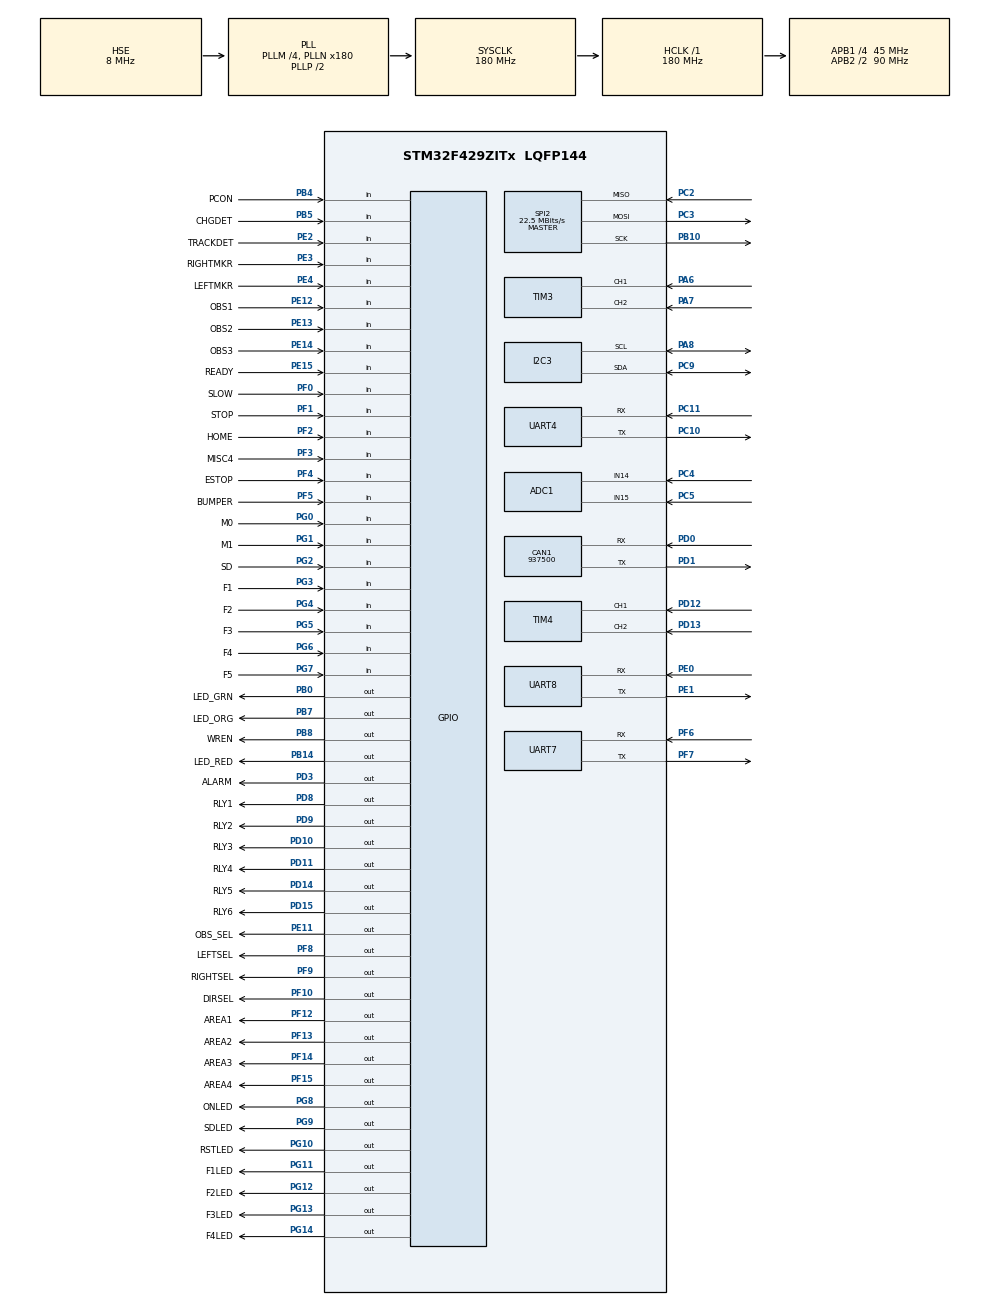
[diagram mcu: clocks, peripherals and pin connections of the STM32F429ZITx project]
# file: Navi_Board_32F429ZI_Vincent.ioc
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ADC1.Channel-0\#ChannelRegularConversion=ADC_CHANNEL_15
ADC1.NbrOfConversionFlag=1
ADC1.Rank-0\#ChannelRegularConversion=1
ADC1.SamplingTime-0\#ChannelRegularConversion=ADC_SAMPLETIME_3CYCLES
ADC1.master=1
CAN1.CalculateBaudRate=937500
CAN1.CalculateTimeBit=1066
CAN1.CalculateTimeQuantum=355.55555555555554
Dma.Request0=UART4_RX
Dma.Request1=UART7_RX
Dma.Request2=UART8_RX
Dma.UART4_RX.0.Direction=DMA_PERIPH_TO_MEMORY
Dma.UART4_RX.0.FIFOMode=DMA_FIFOMODE_DISABLE
Dma.UART4_RX.0.Instance=DMA1_Stream2
Dma.UART4_RX.0.MemDataAlignment=DMA_MDATAALIGN_BYTE
Dma.UART4_RX.0.MemInc=DMA_MINC_ENABLE
Dma.UART4_RX.0.Mode=DMA_NORMAL
Dma.UART4_RX.0.PeriphDataAlignment=DMA_PDATAALIGN_BYTE
Dma.UART4_RX.0.PeriphInc=DMA_PINC_DISABLE
Dma.UART4_RX.0.Priority=DMA_PRIORITY_LOW
Dma.UART7_RX.1.Direction=DMA_PERIPH_TO_MEMORY
Dma.UART7_RX.1.FIFOMode=DMA_FIFOMODE_DISABLE
Dma.UART7_RX.1.Instance=DMA1_Stream3
Dma.UART7_RX.1.MemDataAlignment=DMA_MDATAALIGN_BYTE
Dma.UART7_RX.1.MemInc=DMA_MINC_ENABLE
Dma.UART7_RX.1.Mode=DMA_NORMAL
Dma.UART7_RX.1.PeriphDataAlignment=DMA_PDATAALIGN_BYTE
Dma.UART7_RX.1.PeriphInc=DMA_PINC_DISABLE
Dma.UART7_RX.1.Priority=DMA_PRIORITY_LOW
Dma.UART8_RX.2.Direction=DMA_PERIPH_TO_MEMORY
Dma.UART8_RX.2.FIFOMode=DMA_FIFOMODE_DISABLE
Dma.UART8_RX.2.Instance=DMA1_Stream6
Dma.UART8_RX.2.MemDataAlignment=DMA_MDATAALIGN_BYTE
Dma.UART8_RX.2.MemInc=DMA_MINC_ENABLE
Dma.UART8_RX.2.Mode=DMA_NORMAL
Dma.UART8_RX.2.PeriphDataAlignment=DMA_PDATAALIGN_BYTE
Dma.UART8_RX.2.PeriphInc=DMA_PINC_DISABLE
Dma.UART8_RX.2.Priority=DMA_PRIORITY_LOW
FREERTOS.INCLUDE_vTaskDelayUntil=1
FREERTOS.Tasks01=PCTask,2,128,StartPcTask,Default,NULL,Dynamic,NULL,NULL;MotorTask,-2,128,StartMotorTask,Default,NULL,Dynamic,NULL,NULL;ActionTask,-1,128,StartActionTask,Default,NULL,Dynamic,NULL,NULL;IOTask,0,128,StartIOControlTask,Default,NULL,Dynamic,NULL,NULL
FREERTOS.configUSE_NEWLIB_REENTRANT=1
IWDG.Prescaler=IWDG_PRESCALER_16
IWDG.Reload=3999
Mcu.Family=STM32F4
Mcu.Name=STM32F429ZITx
Mcu.Package=LQFP144
NVIC.DMA1_Stream2_IRQn=true\:5\:0\:true\:false\:true\:true\:false\:true\:true
NVIC.DMA1_Stream3_IRQn=true\:5\:0\:true\:false\:true\:true\:false\:true\:true
NVIC.DMA1_Stream6_IRQn=true\:5\:0\:false\:false\:true\:true\:false\:true\:true
NVIC.PriorityGroup=NVIC_PRIORITYGROUP_4
NVIC.TIM3_IRQn=true\:5\:0\:false\:false\:true\:true\:true\:true\:true
NVIC.TIM4_IRQn=true\:5\:0\:false\:false\:true\:true\:true\:true\:true
NVIC.TIM6_DAC_IRQn=true\:15\:0\:false\:false\:true\:false\:false\:true\:true
NVIC.TimeBase=TIM6_DAC_IRQn
NVIC.TimeBaseIP=TIM6
NVIC.UART4_IRQn=true\:5\:0\:true\:false\:true\:true\:true\:true\:true
NVIC.UART7_IRQn=true\:5\:0\:true\:false\:true\:true\:true\:true\:true
NVIC.UART8_IRQn=true\:5\:0\:false\:false\:true\:true\:true\:true\:true
PA0/WKUP.Signal=S_TIM5_CH1
PA1.Signal=S_TIM5_CH2
PA10.Signal=USART1_RX
PA12.Signal=USART1_RTS
PA13.Mode=Trace_Asynchronous_SW
PA13.Signal=SYS_JTMS-SWDIO
PA14.Mode=Trace_Asynchronous_SW
PA14.Signal=SYS_JTCK-SWCLK
PA2.Signal=USART2_TX
PA3.Signal=USART2_RX
PA6.Signal=S_TIM3_CH1
PA7.Signal=S_TIM3_CH2
PA8.Mode=I2C
PA8.Signal=I2C3_SCL
PA9.Signal=USART1_TX
PB0.GPIO_Label=LED_GRN
PB0.Signal=GPIO_Output
PB10.Mode=Full_Duplex_Master
PB10.Signal=SPI2_SCK
PB12.Signal=SPI2_NSS
PB14.GPIO_Label=LED_RED
PB14.Signal=GPIO_Output
PB3.Mode=Trace_Asynchronous_SW
PB3.Signal=SYS_JTDO-SWO
PB4.GPIO_Label=PCON
PB4.Signal=GPIO_Input
PB5.GPIO_Label=CHGDET
PB5.Signal=GPIO_Input
PB6.Signal=I2C1_SCL
PB7.GPIO_Label=LED_ORG
PB7.Signal=GPIO_Output
PB8.GPIO_Label=WREN
PB8.Signal=GPIO_Output
PC10.Mode=Asynchronous
PC10.Signal=UART4_TX
PC11.Mode=Asynchronous
PC11.Signal=UART4_RX
PC12.Signal=UART5_TX
PC2.Mode=Full_Duplex_Master
PC2.Signal=SPI2_MISO
PC3.Mode=Full_Duplex_Master
PC3.Signal=SPI2_MOSI
PC4.Signal=ADCx_IN14
PC5.Signal=ADCx_IN15
PC9.Mode=I2C
PC9.Signal=I2C3_SDA
PD0.Mode=CAN_Activate
PD0.Signal=CAN1_RX
PD1.Mode=CAN_Activate
PD1.Signal=CAN1_TX
PD10.GPIO_Label=RLY3
PD10.Signal=GPIO_Output
PD11.GPIO_Label=RLY4
PD11.Signal=GPIO_Output
PD12.Signal=S_TIM4_CH1
PD13.Signal=S_TIM4_CH2
PD14.GPIO_Label=RLY5
PD14.Signal=GPIO_Output
PD15.GPIO_Label=RLY6
PD15.Signal=GPIO_Output
PD2.Signal=UART5_RX
PD3.GPIO_Label=ALARM
PD3.Signal=GPIO_Output
PD8.GPIO_Label=RLY1
PD8.Signal=GPIO_Output
PD9.GPIO_Label=RLY2
PD9.Signal=GPIO_Output
PE0.Mode=Asynchronous
PE0.Signal=UART8_RX
PE1.Mode=Asynchronous
PE1.Signal=UART8_TX
PE11.GPIO_Label=OBS_SEL
PE11.Signal=GPIO_Output
PE12.GPIO_Label=OBS1
PE12.Signal=GPIO_Input
PE13.GPIO_Label=OBS2
PE13.Signal=GPIO_Input
PE14.GPIO_Label=OBS3
PE14.Signal=GPIO_Input
PE15.GPIO_Label=READY
PE15.Signal=GPIO_Input
PE2.GPIO_Label=TRACKDET
PE2.Signal=GPIO_Input
PE3.GPIO_Label=RIGHTMKR
PE3.Signal=GPIO_Input
PE4.GPIO_Label=LEFTMKR
PE4.Signal=GPIO_Input
PE5.Signal=S_TIM9_CH1
PE6.Signal=S_TIM9_CH2
PE9.Signal=S_TIM1_CH1
PF0.GPIO_Label=SLOW
PF0.Signal=GPIO_Input
PF1.GPIO_Label=STOP
PF1.Signal=GPIO_Input
PF10.GPIO_Label=DIRSEL
PF10.Signal=GPIO_Output
PF12.GPIO_Label=AREA1
PF12.Signal=GPIO_Output
PF13.GPIO_Label=AREA2
PF13.Signal=GPIO_Output
PF14.GPIO_Label=AREA3
PF14.Signal=GPIO_Output
PF15.GPIO_Label=AREA4
PF15.Signal=GPIO_Output
PF2.GPIO_Label=HOME
PF2.Signal=GPIO_Input
PF3.GPIO_Label=MISC4
PF3.Signal=GPIO_Input
PF4.GPIO_Label=ESTOP
PF4.Signal=GPIO_Input
PF5.GPIO_Label=BUMPER
PF5.Signal=GPIO_Input
PF6.Mode=Asynchronous
PF6.Signal=UART7_RX
PF7.Mode=Asynchronous
PF7.Signal=UART7_TX
PF8.GPIO_Label=LEFTSEL
PF8.Signal=GPIO_Output
PF9.GPIO_Label=RIGHTSEL
PF9.Signal=GPIO_Output
PG0.GPIO_Label=M0
PG0.Signal=GPIO_Input
PG1.GPIO_Label=M1
PG1.Signal=GPIO_Input
PG10.GPIO_Label=RSTLED
PG10.Signal=GPIO_Output
PG11.GPIO_Label=F1LED
PG11.Signal=GPIO_Output
PG12.GPIO_Label=F2LED
PG12.Signal=GPIO_Output
PG13.GPIO_Label=F3LED
PG13.Signal=GPIO_Output
PG14.GPIO_Label=F4LED
PG14.Signal=GPIO_Output
PG2.GPIO_Label=SD
PG2.Signal=GPIO_Input
PG3.GPIO_Label=F1
PG3.Signal=GPIO_Input
PG4.GPIO_Label=F2
PG4.Signal=GPIO_Input
PG5.GPIO_Label=F3
PG5.Signal=GPIO_Input
PG6.GPIO_Label=F4
PG6.Signal=GPIO_Input
PG7.GPIO_Label=F5
PG7.Signal=GPIO_Input
PG8.GPIO_Label=ONLED
PG8.Signal=GPIO_Output
PG9.GPIO_Label=SDLED
PG9.Signal=GPIO_Output
PH0/OSC_IN.Mode=HSE-External-Oscillator
PH0/OSC_IN.Signal=RCC_OSC_IN
PH1/OSC_OUT.Mode=HSE-External-Oscillator
PH1/OSC_OUT.Signal=RCC_OSC_OUT
ProjectManager.HeapSize=0x200
ProjectManager.StackSize=0x400
ProjectManager.TargetToolchain=STM32CubeIDE
RCC.48MHZClocksFreq_Value=90000000
RCC.AHBFreq_Value=180000000
RCC.APB1CLKDivider=RCC_HCLK_DIV4
RCC.APB1Freq_Value=45000000
RCC.APB1TimFreq_Value=90000000
RCC.APB2CLKDivider=RCC_HCLK_DIV2
RCC.APB2Freq_Value=90000000
RCC.APB2TimFreq_Value=180000000
RCC.CortexFreq_Value=180000000
RCC.HCLKFreq_Value=180000000
RCC.HSE_VALUE=8000000
RCC.HSI_VALUE=16000000
RCC.LSE_VALUE=32768
RCC.PLLM=4
RCC.PLLN=180
RCC.PLLSourceVirtual=RCC_PLLSOURCE_HSE
RCC.SYSCLKFreq_VALUE=180000000
RCC.SYSCLKSource=RCC_SYSCLKSOURCE_PLLCLK
RCC.VCOOutputFreq_Value=360000000
SH.ADCx_IN14.0=ADC1_IN14,IN14
SH.ADCx_IN15.0=ADC1_IN15,IN15
SH.S_TIM1_CH1.0=TIM1_CH1
SH.S_TIM3_CH1.0=TIM3_CH1,Encoder_Interface
SH.S_TIM3_CH2.0=TIM3_CH2,Encoder_Interface
SH.S_TIM4_CH1.0=TIM4_CH1,Encoder_Interface
SH.S_TIM4_CH2.0=TIM4_CH2,Encoder_Interface
SH.S_TIM5_CH1.0=TIM5_CH1
SH.S_TIM5_CH2.0=TIM5_CH2
SH.S_TIM9_CH1.0=TIM9_CH1
SH.S_TIM9_CH2.0=TIM9_CH2
SPI2.CalculateBaudRate=22.5 MBits/s
SPI2.Direction=SPI_DIRECTION_2LINES
SPI2.Mode=SPI_MODE_MASTER
SPI2.VirtualType=VM_MASTER
TIM3.EncoderMode=TIM_ENCODERMODE_TI12
TIM4.EncoderMode=TIM_ENCODERMODE_TI12
UART4.VirtualMode=Asynchronous
UART7.VirtualMode=Asynchronous
UART8.VirtualMode=Asynchronous
VP_FREERTOS_VS_CMSIS_V1.Mode=CMSIS_V1
VP_IWDG_VS_IWDG.Mode=IWDG_Activate
VP_SYS_VS_tim6.Mode=TIM6
board=custom

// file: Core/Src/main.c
/* USER CODE BEGIN Header */
/**
  ******************************************************************************
  * @file           : main.c
  * @brief          : Main program body
  ******************************************************************************
  * @attention
  *
  * Copyright (c) 2022 STMicroelectronics.
  * All rights reserved.
  *
  * This software is licensed under terms that can be found in the LICENSE file
  * in the root directory of this software component.
  * If no LICENSE file comes with this software, it is provided AS-IS.
  *
  ******************************************************************************
  */
/* USER CODE END Header */
#include "main.h"
#include "cmsis_os.h"

/* USER CODE BEGIN Includes */
#include "roboteq_HAL.h"
#include "stdio.h"
/* USER CODE END Includes */

/* USER CODE BEGIN PTD */
/** \brief Structure layout that contains the version number of a software
 *         program.
 */
typedef struct
{
  uint8_t major;  /**< Major part of the version number. */
  uint8_t minor;  /**< Minor part of the version number. */
  uint8_t patch;  /**< Patch part of the version number. */
} tVersionInfo;
/** \brief Function-like macro for reading out the bootloader's version
 *         number.
 */
#define FIRM_VERSION_GET()  ((tVersionInfo const * const)0x080001ac)

/** \brief Constant variable that contains the bootloader version number.
 *         The ".version" section attribute was added, allowing the linker
 *         to find it and place it at a fixed address in the memory map.
 *         Note that approach is GCC compiler/linker specific and will
 *         need adjusting in case another toolchain is used.
 */
const tVersionInfo FirmwareVersion __attribute__ ((section (".version"))) =
{
  .major = FIRM_VERSION_CORE_MAIN,
  .minor = FIRM_VERSION_CORE_MINOR,
  .patch = FIRM_VERSION_CORE_PATCH
};
/* USER CODE END PTD */

/* USER CODE BEGIN PM */
#define ITM_Port32(n)   (*((volatile unsigned long *)(0xE0000000+4*n)))
/* USER CODE END PM */

 ADC_HandleTypeDef hadc1;

CAN_HandleTypeDef hcan1;

I2C_HandleTypeDef hi2c3;

IWDG_HandleTypeDef hiwdg;

SPI_HandleTypeDef hspi2;

TIM_HandleTypeDef htim3;
TIM_HandleTypeDef htim4;

UART_HandleTypeDef huart4;
UART_HandleTypeDef huart7;
UART_HandleTypeDef huart8;
DMA_HandleTypeDef hdma_uart4_rx;
DMA_HandleTypeDef hdma_uart7_rx;
DMA_HandleTypeDef hdma_uart8_rx;

osThreadId PCTaskHandle;
osThreadId MotorTaskHandle;
osThreadId ActionTaskHandle;
osThreadId IOTaskHandle;
/* USER CODE BEGIN PV */
uint8_t FirmVersionMajor;
uint8_t FirmVersionMinor;
uint8_t FirmVersionPatch;

uint32_t counter_l = 0;
uint32_t counter_r = 0;
int16_t count_l = 0;
int16_t count_r = 0;
int16_t speed_l;
int16_t speed_r;
int32_t oldpos_l = 0;
int32_t oldpos_r = 0;
uint8_t indx = 0;

int32_t min_enc_value = -32768;
int32_t max_enc_value = 32767;
int32_t prev_lencoder = 0;
int32_t prev_rencoder = 0;
int32_t enc;

int32_t lmult = 0;
int32_t rmult = 0;

int32_t left = 1;
int32_t right = 1;

int32_t encoder_min = -32768;  //-2,147,483,648; //-65536;
int32_t encoder_max = 32767;  // 2,147,483,647; //65536;
int32_t encoder_low_wrap;
int32_t encoder_high_wrap;

extern FLAG fUART_roboteq;
extern FLAG fUART_deck;
extern FLAG fUART_lifter;
extern FLAG fUART_pc;
extern struct {
	float2int wheel_circumference;
	float2int track_width;
	float2int upper_linear_v;
	float2int slow_linear_v;
	uint8_t gear_ratio;
	int32int8 cpr;
	uint8_t deck_gear_ratio;
	int32int8 deck_cpr;
}motorpara;
extern int32_t TIMEOUT;
extern uint32_t motion_exec_state;
/* USER CODE END PV */

void SystemClock_Config(void);
static void MX_GPIO_Init(void);
static void MX_ADC1_Init(void);
static void MX_DMA_Init(void);
static void MX_CAN1_Init(void);
static void MX_I2C3_Init(void);
static void MX_IWDG_Init(void);
static void MX_SPI2_Init(void);
static void MX_TIM3_Init(void);
static void MX_TIM4_Init(void);
static void MX_UART4_Init(void);
static void MX_UART7_Init(void);
static void MX_UART8_Init(void);
void StartPcTask(void const * argument);
void StartMotorTask(void const * argument);
void StartActionTask(void const * argument);
void StartIOControlTask(void const * argument);

/* USER CODE BEGIN PFP */
extern uint8_t Roboteq_Init (void);
extern void Sending_Data2Pc_callback(int interval_rate);
extern uint8_t Pc_Init();
extern uint8_t Deck_Init();
extern void IO_Control();
extern void Exec_Action();
extern void Send_Querydata2PC();
extern void Receive_PC_Command();
extern void Led_Green();
/* USER CODE END PFP */
void TIM1_IC_INT(TIM_HandleTypeDef* htim);
int MagTapePos(void);

/* USER CODE BEGIN 0 */
int _write(int file, char *ptr, int len)
{
  /* Implement your write code here, this is used by puts and printf for example */
  int i=0;
  for(i=0 ; i<len ; i++)
    ITM_SendChar((*ptr++));
  return len;
}
/* USER CODE END 0 */

int main(void)
{

  /* MCU Configuration--------------------------------------------------------*/

  /* Reset of all peripherals, Initializes the Flash interface and the Systick. */
  HAL_Init();

  /* Configure the system clock */
  SystemClock_Config();

  /* USER CODE BEGIN SysInit */
  ITM_Port32(31) = 1;
  /* USER CODE END SysInit */

  /* Initialize all configured peripherals */
  MX_GPIO_Init();
  MX_ADC1_Init();
  MX_DMA_Init();
  MX_CAN1_Init();
  MX_I2C3_Init();
  //MX_IWDG_Init();
  MX_SPI2_Init();
  MX_TIM3_Init();
  MX_TIM4_Init();
  MX_UART4_Init();
  MX_UART7_Init();
  MX_UART8_Init();
  /* USER CODE BEGIN 2 */
  ITM_Port32(31) = 2;
  /* USER CODE END 2 */

  /* Create the thread(s) */
  /* definition and creation of PCTask */
  osThreadDef(PCTask, StartPcTask, osPriorityHigh, 0, 128); //Receive PC command here: priority: HIGH
  PCTaskHandle = osThreadCreate(osThread(PCTask), NULL);

  /* definition and creation of MotorTask */
  osThreadDef(MotorTask, StartMotorTask, osPriorityLow, 0, 128); //Sending Query to the PC
  MotorTaskHandle = osThreadCreate(osThread(MotorTask), NULL);

  /* definition and creation of ActionTask */
  osThreadDef(ActionTask, StartActionTask, osPriorityBelowNormal, 0, 128); //Action Execuation
  ActionTaskHandle = osThreadCreate(osThread(ActionTask), NULL);

  /* definition and creation of IOTask */
  osThreadDef(IOTask, StartIOControlTask, osPriorityNormal, 0, 128); //Initize IOs for the operation
  IOTaskHandle = osThreadCreate(osThread(IOTask), NULL);

  /* Start scheduler */
  osKernelStart(); //Kicks off the main program threads (4x)

  /* We should never get here as control is now taken by the scheduler */
  /* Infinite loop */
  while (1)
  {

  }
}

void SystemClock_Config(void)
{
  RCC_OscInitTypeDef RCC_OscInitStruct = {0};
  RCC_ClkInitTypeDef RCC_ClkInitStruct = {0};

  /** Configure the main internal regulator output voltage
  */
  __HAL_RCC_PWR_CLK_ENABLE();
  __HAL_PWR_VOLTAGESCALING_CONFIG(PWR_REGULATOR_VOLTAGE_SCALE1);

  /** Initializes the RCC Oscillators according to the specified parameters
  * in the RCC_OscInitTypeDef structure.
  */
  RCC_OscInitStruct.OscillatorType = RCC_OSCILLATORTYPE_LSI|RCC_OSCILLATORTYPE_HSE;
  RCC_OscInitStruct.HSEState = RCC_HSE_ON;
  RCC_OscInitStruct.LSIState = RCC_LSI_ON;
  RCC_OscInitStruct.PLL.PLLState = RCC_PLL_ON;
  RCC_OscInitStruct.PLL.PLLSource = RCC_PLLSOURCE_HSE;
  RCC_OscInitStruct.PLL.PLLM = 4;
  RCC_OscInitStruct.PLL.PLLN = 180;
  RCC_OscInitStruct.PLL.PLLP = RCC_PLLP_DIV2;
  RCC_OscInitStruct.PLL.PLLQ = 4;
  if (HAL_RCC_OscConfig(&RCC_OscInitStruct) != HAL_OK)
  {
    Error_Handler();
  }

  /** Activate the Over-Drive mode
  */
  if (HAL_PWREx_EnableOverDrive() != HAL_OK)
  {
    Error_Handler();
  }

  /** Initializes the CPU, AHB and APB buses clocks
  */
  RCC_ClkInitStruct.ClockType = RCC_CLOCKTYPE_HCLK|RCC_CLOCKTYPE_SYSCLK
                              |RCC_CLOCKTYPE_PCLK1|RCC_CLOCKTYPE_PCLK2;
  RCC_ClkInitStruct.SYSCLKSource = RCC_SYSCLKSOURCE_PLLCLK;
  RCC_ClkInitStruct.AHBCLKDivider = RCC_SYSCLK_DIV1;
  RCC_ClkInitStruct.APB1CLKDivider = RCC_HCLK_DIV4;
  RCC_ClkInitStruct.APB2CLKDivider = RCC_HCLK_DIV2;

  if (HAL_RCC_ClockConfig(&RCC_ClkInitStruct, FLASH_LATENCY_5) != HAL_OK)
  {
    Error_Handler();
  }
}

static void MX_ADC1_Init(void)
{

  ADC_ChannelConfTypeDef sConfig = {0};

  /** Configure the global features of the ADC (Clock, Resolution, Data Alignment and number of conversion)
  */
  hadc1.Instance = ADC1;
  hadc1.Init.ClockPrescaler = ADC_CLOCK_SYNC_PCLK_DIV4;
  hadc1.Init.Resolution = ADC_RESOLUTION_12B;
  hadc1.Init.ScanConvMode = DISABLE;
  hadc1.Init.ContinuousConvMode = DISABLE;
  hadc1.Init.DiscontinuousConvMode = DISABLE;
  hadc1.Init.ExternalTrigConvEdge = ADC_EXTERNALTRIGCONVEDGE_NONE;
  hadc1.Init.ExternalTrigConv = ADC_SOFTWARE_START;
  hadc1.Init.DataAlign = ADC_DATAALIGN_RIGHT;
  hadc1.Init.NbrOfConversion = 1;
  hadc1.Init.DMAContinuousRequests = DISABLE;
  hadc1.Init.EOCSelection = ADC_EOC_SINGLE_CONV;
  if (HAL_ADC_Init(&hadc1) != HAL_OK)
  {
    Error_Handler();
  }

  /** Configure for the selected ADC regular channel its corresponding rank in the sequencer and its sample time.
  */
  sConfig.Channel = ADC_CHANNEL_15;
  sConfig.Rank = 1;
  sConfig.SamplingTime = ADC_SAMPLETIME_3CYCLES;
  if (HAL_ADC_ConfigChannel(&hadc1, &sConfig) != HAL_OK)
  {
    Error_Handler();
  }

}

static void MX_CAN1_Init(void)
{

  hcan1.Instance = CAN1;
  hcan1.Init.Prescaler = 16;
  hcan1.Init.Mode = CAN_MODE_NORMAL;
  hcan1.Init.SyncJumpWidth = CAN_SJW_1TQ;
  hcan1.Init.TimeSeg1 = CAN_BS1_1TQ;
  hcan1.Init.TimeSeg2 = CAN_BS2_1TQ;
  hcan1.Init.TimeTriggeredMode = DISABLE;
  hcan1.Init.AutoBusOff = DISABLE;
  hcan1.Init.AutoWakeUp = DISABLE;
  hcan1.Init.AutoRetransmission = DISABLE;
  hcan1.Init.ReceiveFifoLocked = DISABLE;
  hcan1.Init.TransmitFifoPriority = DISABLE;
  if (HAL_CAN_Init(&hcan1) != HAL_OK)
  {
    Error_Handler();
  }

}

static void MX_I2C3_Init(void)
{

  hi2c3.Instance = I2C3;
  hi2c3.Init.ClockSpeed = 100000;
  hi2c3.Init.DutyCycle = I2C_DUTYCYCLE_2;
  hi2c3.Init.OwnAddress1 = 0;
  hi2c3.Init.AddressingMode = I2C_ADDRESSINGMODE_7BIT;
  hi2c3.Init.DualAddressMode = I2C_DUALADDRESS_DISABLE;
  hi2c3.Init.OwnAddress2 = 0;
  hi2c3.Init.GeneralCallMode = I2C_GENERALCALL_DISABLE;
  hi2c3.Init.NoStretchMode = I2C_NOSTRETCH_DISABLE;
  if (HAL_I2C_Init(&hi2c3) != HAL_OK)
  {
    Error_Handler();
  }

  /** Configure Analogue filter
  */
  if (HAL_I2CEx_ConfigAnalogFilter(&hi2c3, I2C_ANALOGFILTER_ENABLE) != HAL_OK)
  {
    Error_Handler();
  }

  /** Configure Digital filter
  */
  if (HAL_I2CEx_ConfigDigitalFilter(&hi2c3, 0) != HAL_OK)
  {
    Error_Handler();
  }

}

static void MX_IWDG_Init(void)
{

  hiwdg.Instance = IWDG;
  hiwdg.Init.Prescaler = IWDG_PRESCALER_16;
  hiwdg.Init.Reload = 3999;
  if (HAL_IWDG_Init(&hiwdg) != HAL_OK)
  {
    Error_Handler();
  }

}

static void MX_SPI2_Init(void)
{

  /* SPI2 parameter configuration*/
  hspi2.Instance = SPI2;
  hspi2.Init.Mode = SPI_MODE_MASTER;
  hspi2.Init.Direction = SPI_DIRECTION_2LINES;
  hspi2.Init.DataSize = SPI_DATASIZE_8BIT;
  hspi2.Init.CLKPolarity = SPI_POLARITY_LOW;
  hspi2.Init.CLKPhase = SPI_PHASE_1EDGE;
  hspi2.Init.NSS = SPI_NSS_SOFT;
  hspi2.Init.BaudRatePrescaler = SPI_BAUDRATEPRESCALER_2;
  hspi2.Init.FirstBit = SPI_FIRSTBIT_MSB;
  hspi2.Init.TIMode = SPI_TIMODE_DISABLE;
  hspi2.Init.CRCCalculation = SPI_CRCCALCULATION_DISABLE;
  hspi2.Init.CRCPolynomial = 10;
  if (HAL_SPI_Init(&hspi2) != HAL_OK)
  {
    Error_Handler();
  }

}

static void MX_TIM3_Init(void)
{

  TIM_Encoder_InitTypeDef sConfig = {0};
  TIM_MasterConfigTypeDef sMasterConfig = {0};

  htim3.Instance = TIM3;
  htim3.Init.Prescaler = 0;
  htim3.Init.CounterMode = TIM_COUNTERMODE_UP;
  htim3.Init.Period = 65535;
  htim3.Init.ClockDivision = TIM_CLOCKDIVISION_DIV1;
  htim3.Init.AutoReloadPreload = TIM_AUTORELOAD_PRELOAD_DISABLE;
  sConfig.EncoderMode = TIM_ENCODERMODE_TI12;
  sConfig.IC1Polarity = TIM_ICPOLARITY_RISING;
  sConfig.IC1Selection = TIM_ICSELECTION_DIRECTTI;
  sConfig.IC1Prescaler = TIM_ICPSC_DIV1;
  sConfig.IC1Filter = 0;
  sConfig.IC2Polarity = TIM_ICPOLARITY_RISING;
  sConfig.IC2Selection = TIM_ICSELECTION_DIRECTTI;
  sConfig.IC2Prescaler = TIM_ICPSC_DIV1;
  sConfig.IC2Filter = 0;
  if (HAL_TIM_Encoder_Init(&htim3, &sConfig) != HAL_OK)
  {
    Error_Handler();
  }
  sMasterConfig.MasterOutputTrigger = TIM_TRGO_RESET;
  sMasterConfig.MasterSlaveMode = TIM_MASTERSLAVEMODE_DISABLE;
  if (HAL_TIMEx_MasterConfigSynchronization(&htim3, &sMasterConfig) != HAL_OK)
  {
    Error_Handler();
  }

}

static void MX_TIM4_Init(void)
{

  TIM_Encoder_InitTypeDef sConfig = {0};
  TIM_MasterConfigTypeDef sMasterConfig = {0};

  htim4.Instance = TIM4;
  htim4.Init.Prescaler = 0;
  htim4.Init.CounterMode = TIM_COUNTERMODE_UP;
  htim4.Init.Period = 65535;
  htim4.Init.ClockDivision = TIM_CLOCKDIVISION_DIV1;
  htim4.Init.AutoReloadPreload = TIM_AUTORELOAD_PRELOAD_DISABLE;
  sConfig.EncoderMode = TIM_ENCODERMODE_TI12;
  sConfig.IC1Polarity = TIM_ICPOLARITY_RISING;
  sConfig.IC1Selection = TIM_ICSELECTION_DIRECTTI;
  sConfig.IC1Prescaler = TIM_ICPSC_DIV1;
  sConfig.IC1Filter = 0;
  sConfig.IC2Polarity = TIM_ICPOLARITY_RISING;
  sConfig.IC2Selection = TIM_ICSELECTION_DIRECTTI;
  sConfig.IC2Prescaler = TIM_ICPSC_DIV1;
  sConfig.IC2Filter = 0;
  if (HAL_TIM_Encoder_Init(&htim4, &sConfig) != HAL_OK)
  {
    Error_Handler();
  }
  sMasterConfig.MasterOutputTrigger = TIM_TRGO_RESET;
  sMasterConfig.MasterSlaveMode = TIM_MASTERSLAVEMODE_DISABLE;
  if (HAL_TIMEx_MasterConfigSynchronization(&htim4, &sMasterConfig) != HAL_OK)
  {
    Error_Handler();
  }

}

static void MX_UART4_Init(void)
{

  huart4.Instance = UART4;
  huart4.Init.BaudRate = 115200;
  huart4.Init.WordLength = UART_WORDLENGTH_8B;
  huart4.Init.StopBits = UART_STOPBITS_1;
  huart4.Init.Parity = UART_PARITY_NONE;
  huart4.Init.Mode = UART_MODE_TX_RX;
  huart4.Init.HwFlowCtl = UART_HWCONTROL_NONE;
  huart4.Init.OverSampling = UART_OVERSAMPLING_16;
  if (HAL_UART_Init(&huart4) != HAL_OK)
  {
    Error_Handler();
  }

}

static void MX_UART7_Init(void)
{

  huart7.Instance = UART7;
  huart7.Init.BaudRate = 115200;
  huart7.Init.WordLength = UART_WORDLENGTH_8B;
  huart7.Init.StopBits = UART_STOPBITS_1;
  huart7.Init.Parity = UART_PARITY_NONE;
  huart7.Init.Mode = UART_MODE_TX_RX;
  huart7.Init.HwFlowCtl = UART_HWCONTROL_NONE;
  huart7.Init.OverSampling = UART_OVERSAMPLING_16;
  if (HAL_UART_Init(&huart7) != HAL_OK)
  {
    Error_Handler();
  }

}

static void MX_UART8_Init(void)
{

  huart8.Instance = UART8;
  huart8.Init.BaudRate = 115200;
  huart8.Init.WordLength = UART_WORDLENGTH_8B;
  huart8.Init.StopBits = UART_STOPBITS_1;
  huart8.Init.Parity = UART_PARITY_NONE;
  huart8.Init.Mode = UART_MODE_TX_RX;
  huart8.Init.HwFlowCtl = UART_HWCONTROL_NONE;
  huart8.Init.OverSampling = UART_OVERSAMPLING_16;
  if (HAL_UART_Init(&huart8) != HAL_OK)
  {
    Error_Handler();
  }

}

static void MX_DMA_Init(void)
{

  /* DMA controller clock enable */
  __HAL_RCC_DMA1_CLK_ENABLE();

  /* DMA interrupt init */
  /* DMA1_Stream2_IRQn interrupt configuration */
  HAL_NVIC_SetPriority(DMA1_Stream2_IRQn, 5, 0);
  HAL_NVIC_EnableIRQ(DMA1_Stream2_IRQn);
  /* DMA1_Stream3_IRQn interrupt configuration */
  HAL_NVIC_SetPriority(DMA1_Stream3_IRQn, 5, 0);
  HAL_NVIC_EnableIRQ(DMA1_Stream3_IRQn);
  /* DMA1_Stream6_IRQn interrupt configuration */
  HAL_NVIC_SetPriority(DMA1_Stream6_IRQn, 5, 0);
  HAL_NVIC_EnableIRQ(DMA1_Stream6_IRQn);

}

static void MX_GPIO_Init(void)
{
  GPIO_InitTypeDef GPIO_InitStruct = {0};

  /* GPIO Ports Clock Enable */
  __HAL_RCC_GPIOE_CLK_ENABLE();
  __HAL_RCC_GPIOF_CLK_ENABLE();
  __HAL_RCC_GPIOH_CLK_ENABLE();
  __HAL_RCC_GPIOC_CLK_ENABLE();
  __HAL_RCC_GPIOA_CLK_ENABLE();
  __HAL_RCC_GPIOB_CLK_ENABLE();
  __HAL_RCC_GPIOG_CLK_ENABLE();
  __HAL_RCC_GPIOD_CLK_ENABLE();

  /*Configure GPIO pin Output Level */
  HAL_GPIO_WritePin(GPIOF, LEFTSEL_Pin|RIGHTSEL_Pin|DIRSEL_Pin|AREA1_Pin
                          |AREA2_Pin|AREA3_Pin|AREA4_Pin, GPIO_PIN_RESET);

  /*Configure GPIO pin Output Level */
  HAL_GPIO_WritePin(GPIOB, LED_GRN_Pin|LED_RED_Pin|LED_ORG_Pin|WREN_Pin, GPIO_PIN_RESET);

  /*Configure GPIO pin Output Level */
  HAL_GPIO_WritePin(OBS_SEL_GPIO_Port, OBS_SEL_Pin, GPIO_PIN_RESET);

  /*Configure GPIO pin Output Level */
  HAL_GPIO_WritePin(GPIOD, RLY1_Pin|RLY2_Pin|RLY3_Pin|RLY4_Pin
                          |RLY5_Pin|RLY6_Pin|ALARM_Pin, GPIO_PIN_RESET);

  /*Configure GPIO pin Output Level */
  HAL_GPIO_WritePin(GPIOG, ONLED_Pin|SDLED_Pin|RSTLED_Pin|F1LED_Pin
                          |F2LED_Pin|F3LED_Pin|F4LED_Pin, GPIO_PIN_RESET);

  /*Configure GPIO pins : TRACKDET_Pin RIGHTMKR_Pin LEFTMKR_Pin OBS1_Pin
                           OBS2_Pin OBS3_Pin READY_Pin */
  GPIO_InitStruct.Pin = TRACKDET_Pin|RIGHTMKR_Pin|LEFTMKR_Pin|OBS1_Pin
                          |OBS2_Pin|OBS3_Pin|READY_Pin;
  GPIO_InitStruct.Mode = GPIO_MODE_INPUT;
  GPIO_InitStruct.Pull = GPIO_NOPULL;
  HAL_GPIO_Init(GPIOE, &GPIO_InitStruct);

  /*Configure GPIO pins : PE5 PE6 */
  GPIO_InitStruct.Pin = GPIO_PIN_5|GPIO_PIN_6;
  GPIO_InitStruct.Mode = GPIO_MODE_AF_PP;
  GPIO_InitStruct.Pull = GPIO_NOPULL;
  GPIO_InitStruct.Speed = GPIO_SPEED_FREQ_LOW;
  GPIO_InitStruct.Alternate = GPIO_AF3_TIM9;
  HAL_GPIO_Init(GPIOE, &GPIO_InitStruct);

  /*Configure GPIO pins : SLOW_Pin STOP_Pin HOME_Pin MISC4_Pin
                           ESTOP_Pin BUMPER_Pin */
  GPIO_InitStruct.Pin = SLOW_Pin|STOP_Pin|HOME_Pin|MISC4_Pin
                          |ESTOP_Pin|BUMPER_Pin;
  GPIO_InitStruct.Mode = GPIO_MODE_INPUT;
  GPIO_InitStruct.Pull = GPIO_NOPULL;
  HAL_GPIO_Init(GPIOF, &GPIO_InitStruct);

  /*Configure GPIO pins : LEFTSEL_Pin RIGHTSEL_Pin DIRSEL_Pin AREA1_Pin
                           AREA2_Pin AREA3_Pin AREA4_Pin */
  GPIO_InitStruct.Pin = LEFTSEL_Pin|RIGHTSEL_Pin|DIRSEL_Pin|AREA1_Pin
                          |AREA2_Pin|AREA3_Pin|AREA4_Pin;
  GPIO_InitStruct.Mode = GPIO_MODE_OUTPUT_PP;
  GPIO_InitStruct.Pull = GPIO_NOPULL;
  GPIO_InitStruct.Speed = GPIO_SPEED_FREQ_LOW;
  HAL_GPIO_Init(GPIOF, &GPIO_InitStruct);

  /*Configure GPIO pins : PA0 PA1 */
  GPIO_InitStruct.Pin = GPIO_PIN_0|GPIO_PIN_1;
  GPIO_InitStruct.Mode = GPIO_MODE_AF_PP;
  GPIO_InitStruct.Pull = GPIO_NOPULL;
  GPIO_InitStruct.Speed = GPIO_SPEED_FREQ_LOW;
  GPIO_InitStruct.Alternate = GPIO_AF2_TIM5;
  HAL_GPIO_Init(GPIOA, &GPIO_InitStruct);

  /*Configure GPIO pins : PA2 PA3 */
  GPIO_InitStruct.Pin = GPIO_PIN_2|GPIO_PIN_3;
  GPIO_InitStruct.Mode = GPIO_MODE_AF_PP;
  GPIO_InitStruct.Pull = GPIO_NOPULL;
  GPIO_InitStruct.Speed = GPIO_SPEED_FREQ_VERY_HIGH;
  GPIO_InitStruct.Alternate = GPIO_AF7_USART2;
  HAL_GPIO_Init(GPIOA, &GPIO_InitStruct);

  /*Configure GPIO pins : LED_GRN_Pin LED_RED_Pin LED_ORG_Pin WREN_Pin */
  GPIO_InitStruct.Pin = LED_GRN_Pin|LED_RED_Pin|LED_ORG_Pin|WREN_Pin;
  GPIO_InitStruct.Mode = GPIO_MODE_OUTPUT_PP;
  GPIO_InitStruct.Pull = GPIO_NOPULL;
  GPIO_InitStruct.Speed = GPIO_SPEED_FREQ_LOW;
  HAL_GPIO_Init(GPIOB, &GPIO_InitStruct);

  /*Configure GPIO pins : M0_Pin M1_Pin SD_Pin F1_Pin
                           F2_Pin F3_Pin F4_Pin F5_Pin */
  GPIO_InitStruct.Pin = M0_Pin|M1_Pin|SD_Pin|F1_Pin
                          |F2_Pin|F3_Pin|F4_Pin|F5_Pin;
  GPIO_InitStruct.Mode = GPIO_MODE_INPUT;
  GPIO_InitStruct.Pull = GPIO_NOPULL;
  HAL_GPIO_Init(GPIOG, &GPIO_InitStruct);

  /*Configure GPIO pin : PE9 */
  GPIO_InitStruct.Pin = GPIO_PIN_9;
  GPIO_InitStruct.Mode = GPIO_MODE_AF_PP;
  GPIO_InitStruct.Pull = GPIO_NOPULL;
  GPIO_InitStruct.Speed = GPIO_SPEED_FREQ_LOW;
  GPIO_InitStruct.Alternate = GPIO_AF1_TIM1;
  HAL_GPIO_Init(GPIOE, &GPIO_InitStruct);

  /*Configure GPIO pin : OBS_SEL_Pin */
  GPIO_InitStruct.Pin = OBS_SEL_Pin;
  GPIO_InitStruct.Mode = GPIO_MODE_OUTPUT_PP;
  GPIO_InitStruct.Pull = GPIO_NOPULL;
  GPIO_InitStruct.Speed = GPIO_SPEED_FREQ_LOW;
  HAL_GPIO_Init(OBS_SEL_GPIO_Port, &GPIO_InitStruct);

  /*Configure GPIO pins : RLY1_Pin RLY2_Pin RLY3_Pin RLY4_Pin
                           RLY5_Pin RLY6_Pin ALARM_Pin */
  GPIO_InitStruct.Pin = RLY1_Pin|RLY2_Pin|RLY3_Pin|RLY4_Pin
                          |RLY5_Pin|RLY6_Pin|ALARM_Pin;
  GPIO_InitStruct.Mode = GPIO_MODE_OUTPUT_PP;
  GPIO_InitStruct.Pull = GPIO_NOPULL;
  GPIO_InitStruct.Speed = GPIO_SPEED_FREQ_LOW;
  HAL_GPIO_Init(GPIOD, &GPIO_InitStruct);

  /*Configure GPIO pins : ONLED_Pin SDLED_Pin RSTLED_Pin F1LED_Pin
                           F2LED_Pin F3LED_Pin F4LED_Pin */
  GPIO_InitStruct.Pin = ONLED_Pin|SDLED_Pin|RSTLED_Pin|F1LED_Pin
                          |F2LED_Pin|F3LED_Pin|F4LED_Pin;
  GPIO_InitStruct.Mode = GPIO_MODE_OUTPUT_PP;
  GPIO_InitStruct.Pull = GPIO_NOPULL;
  GPIO_InitStruct.Speed = GPIO_SPEED_FREQ_LOW;
  HAL_GPIO_Init(GPIOG, &GPIO_InitStruct);

  /*Configure GPIO pins : PA9 PA10 PA12 */
  GPIO_InitStruct.Pin = GPIO_PIN_9|GPIO_PIN_10|GPIO_PIN_12;
  GPIO_InitStruct.Mode = GPIO_MODE_AF_PP;
  GPIO_InitStruct.Pull = GPIO_NOPULL;
  GPIO_InitStruct.Speed = GPIO_SPEED_FREQ_VERY_HIGH;
  GPIO_InitStruct.Alternate = GPIO_AF7_USART1;
  HAL_GPIO_Init(GPIOA, &GPIO_InitStruct);

  /*Configure GPIO pin : PC12 */
  GPIO_InitStruct.Pin = GPIO_PIN_12;
  GPIO_InitStruct.Mode = GPIO_MODE_AF_PP;
  GPIO_InitStruct.Pull = GPIO_NOPULL;
  GPIO_InitStruct.Speed = GPIO_SPEED_FREQ_VERY_HIGH;
  GPIO_InitStruct.Alternate = GPIO_AF8_UART5;
  HAL_GPIO_Init(GPIOC, &GPIO_InitStruct);

  /*Configure GPIO pin : PD2 */
  GPIO_InitStruct.Pin = GPIO_PIN_2;
  GPIO_InitStruct.Mode = GPIO_MODE_AF_PP;
  GPIO_InitStruct.Pull = GPIO_NOPULL;
  GPIO_InitStruct.Speed = GPIO_SPEED_FREQ_VERY_HIGH;
  GPIO_InitStruct.Alternate = GPIO_AF8_UART5;
  HAL_GPIO_Init(GPIOD, &GPIO_InitStruct);

  /*Configure GPIO pins : PCON_Pin CHGDET_Pin */
  GPIO_InitStruct.Pin = PCON_Pin|CHGDET_Pin;
  GPIO_InitStruct.Mode = GPIO_MODE_INPUT;
  GPIO_InitStruct.Pull = GPIO_NOPULL;
  HAL_GPIO_Init(GPIOB, &GPIO_InitStruct);

  /*Configure GPIO pin : PB6 */
  GPIO_InitStruct.Pin = GPIO_PIN_6;
  GPIO_InitStruct.Mode = GPIO_MODE_AF_OD;
  GPIO_InitStruct.Pull = GPIO_NOPULL;
  GPIO_InitStruct.Speed = GPIO_SPEED_FREQ_VERY_HIGH;
  GPIO_InitStruct.Alternate = GPIO_AF4_I2C1;
  HAL_GPIO_Init(GPIOB, &GPIO_InitStruct);

}

/* USER CODE BEGIN 4 */
void HAL_TIM_IC_CaptureCallback(TIM_HandleTypeDef *htim)
{
	if(htim == &htim3){
		counter_l = __HAL_TIM_GET_COUNTER(htim);

		enc = (int16_t)counter_l;

		if ((enc < encoder_low_wrap) && (prev_lencoder > encoder_high_wrap)){
			lmult = lmult + 1;
		}

		if ((enc > encoder_high_wrap) && (prev_lencoder < encoder_low_wrap)){
			lmult = lmult - 1;
		}

		left = 1.0 * (enc + lmult * (encoder_max - encoder_min));
		prev_lencoder = enc;
	}else if(htim == &htim4){
		counter_r = __HAL_TIM_GET_COUNTER(htim);

		enc = (int16_t)counter_r;

		if ((enc < encoder_low_wrap) && (prev_rencoder > encoder_high_wrap)){
			rmult = rmult + 1;
		}

		if ((enc > encoder_high_wrap) && (prev_rencoder < encoder_low_wrap)){
			rmult = rmult - 1;
		}

		right = 1.0 * (enc + rmult * (encoder_max - encoder_min));
		prev_rencoder = enc;
	}
}
/* USER CODE END 4 */

void StartPcTask(void const * argument)
{
  /* USER CODE BEGIN 5 */
	/* Read firmware version. */
	FirmVersionMajor = FIRM_VERSION_GET()->major;
	FirmVersionMinor = FIRM_VERSION_GET()->minor;
	FirmVersionPatch = FIRM_VERSION_GET()->patch;
	isPCFailInit = TRUE;
	for (int i=0; i<PC_RETRY_TIMES;i++){
	  if (Pc_Init() == TRUE){
		  isPCFailInit = FALSE;
		  break;
	  }
	  HAL_Delay(1000);
	}
	if (motorpara.deck_gear_ratio == 0 && motorpara.deck_cpr.i32 == 0){
	  isDeckOption = FALSE;
	} else {
	  isDeckOption = TRUE;
	}
	isFailInit = TRUE;
	for (int i=0; i<ROBOTEQ_RETRY_TIMES;i++){
	  if (Roboteq_Init() == TRUE){
		  isFailInit = FALSE;
		  break;
	  }
	  HAL_Delay(1000);
	}
	if (isDeckOption == TRUE){
	  isDeckFailInit = TRUE;
	  for (int i=0; i<ROBOTEQ_RETRY_TIMES;i++){
		  if (Deck_Init() == TRUE){
			  isDeckFailInit = FALSE;
			  break;
		  }
		  HAL_Delay(1000);
	  }
	}
	HAL_TIM_Encoder_Start_IT(&htim3, TIM_CHANNEL_ALL);
	HAL_TIM_Encoder_Start_IT(&htim4, TIM_CHANNEL_ALL);
	encoder_low_wrap = ((encoder_max - encoder_min) * 0.3) + encoder_min;
	encoder_high_wrap = ((encoder_max - encoder_min) * 0.7) + encoder_min;
  /* Infinite loop */
  for(;;)
  {
	uint32_t PreviousWakeTime = osKernelSysTick();
	Receive_PC_Command();
	osDelayUntil(&PreviousWakeTime, 25);
  }
  /* USER CODE END 5 */
}

void StartMotorTask(void const * argument)
{
  /* USER CODE BEGIN StartMotorTask */
  /* Infinite loop */
  for(;;)
  {
	  ITM_Port32(31) = 1;
	uint32_t PreviousWakeTime = osKernelSysTick();
	Send_Querydata2PC();
	  ITM_Port32(31) = 2;
	osDelayUntil(&PreviousWakeTime, 50);
  }
  /* USER CODE END StartMotorTask */
}

void StartActionTask(void const * argument)
{
  /* USER CODE BEGIN StartActionTask */
  /* Infinite loop */
//	MX_IWDG_Init();
  for(;;)
  {
	  uint32_t PreviousWakeTime = osKernelSysTick();
	  Exec_Action();
	  osDelayUntil(&PreviousWakeTime, 25);
//	  HAL_IWDG_Refresh(&hiwdg);		// Watchdog Refresh
  }
  /* USER CODE END StartActionTask */
}

void StartIOControlTask(void const * argument)
{
  /* USER CODE BEGIN StartIOControlTask */
  /* Infinite loop */
  for(;;)
  {
	uint32_t PreviousWakeTime = osKernelSysTick();
	IO_Control();
	osDelayUntil(&PreviousWakeTime, 50);
  }
  /* USER CODE END StartIOControlTask */
}

void HAL_TIM_PeriodElapsedCallback(TIM_HandleTypeDef *htim)
{
  if (htim->Instance == TIM6) {
    HAL_IncTick();
    TIMEOUT--;
	indx++;

	if (indx == 50)
	{
		speed_l = ((left - oldpos_l)*12/8);
		speed_r = ((right - oldpos_r)*12/8);
		oldpos_l = left;
		oldpos_r = right;
		indx = 0;
		Led_Status_display();
	}
  }
}

void Error_Handler(void)
{
  __disable_irq();
  while (1)
  {
  }
}
